# ICSSM0_COMMON_0_IEP0 register map
Vendor: Texas Instruments
Peripheral module from a debugger description file (folder am62x).
Registers are 32-bit, read-write, reset 0x0 unless marked. A register's access mark holds for its fields unless they carry their own. Offsets are as the file gives them; lines under a group give offsets from that group; [hi:lo] are bit positions; {n}, {i} and the like mark numbered series; 'fields as' and 'values as' point back to an identical list; <NAME> marks a mode.

## ICSSM0_COMMON_0_IEP0
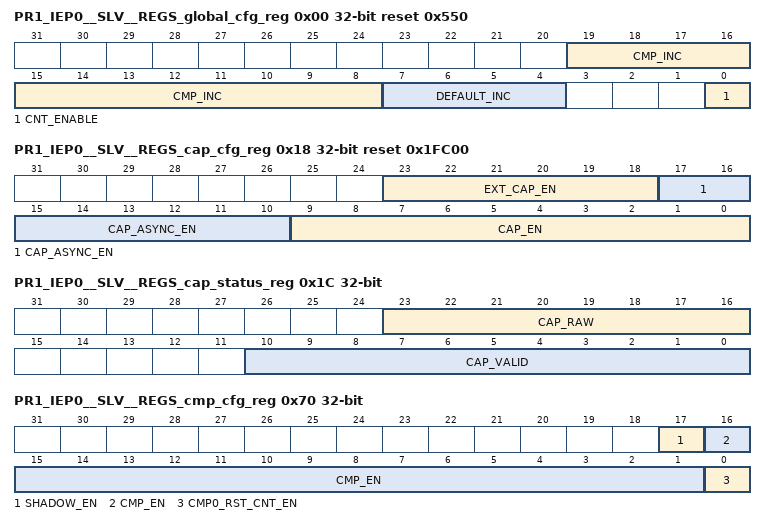
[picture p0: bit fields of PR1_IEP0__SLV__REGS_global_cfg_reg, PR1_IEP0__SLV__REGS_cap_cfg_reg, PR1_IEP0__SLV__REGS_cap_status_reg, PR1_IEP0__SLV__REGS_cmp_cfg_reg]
0x00 PR1_IEP0__SLV__REGS_global_cfg_reg reset 0x550
  [19:8] CMP_INC, [7:4] DEFAULT_INC, [0] CNT_ENABLE
0x04 PR1_IEP0__SLV__REGS_global_status_reg access not given
  [0] CNT_OVF — (access R/W1TC)
0x08 PR1_IEP0__SLV__REGS_compen_reg
  [22:0] COMPEN_CNT
0x0C PR1_IEP0__SLV__REGS_slow_compen_reg
  [31:0] SLOW_COMPEN_CNT
0x10 PR1_IEP0__SLV__REGS_count_reg0
  [31:0] COUNT_LO
0x14 PR1_IEP0__SLV__REGS_count_reg1
  [31:0] COUNT_HI
0x18 PR1_IEP0__SLV__REGS_cap_cfg_reg reset 0x1FC00
  [23:18] EXT_CAP_EN, [17:10] CAP_ASYNC_EN, [9:0] CAP_EN
0x1C PR1_IEP0__SLV__REGS_cap_status_reg ro
  [23:16] CAP_RAW, [10:0] CAP_VALID
{0x20+8i} PR1_IEP0__SLV__REGS_capr{i}_reg0 ro (i=0..6)
  [31:0] CAPR{i}_0
{0x24+8i} PR1_IEP0__SLV__REGS_capr{i}_reg1 ro (i=0..6)
  [31:0] CAPR{i}_1
0x58 PR1_IEP0__SLV__REGS_capf6_reg0 ro
  [31:0] CAPF6_0
0x5C PR1_IEP0__SLV__REGS_capf6_reg1 ro
  [31:0] CAPF6_1
0x60 PR1_IEP0__SLV__REGS_capr7_reg0 ro
  [31:0] CAPR7_0
0x64 PR1_IEP0__SLV__REGS_capr7_reg1 ro
  [31:0] CAPR7_1
0x68 PR1_IEP0__SLV__REGS_capf7_reg0 ro
  [31:0] CAPF7_0
0x6C PR1_IEP0__SLV__REGS_capf7_reg1 ro
  [31:0] CAPF7_1
0x70 PR1_IEP0__SLV__REGS_cmp_cfg_reg
  [17] SHADOW_EN, [16:1] CMP_EN, [0] CMP0_RST_CNT_EN
0x74 PR1_IEP0__SLV__REGS_cmp_status_reg access not given
  [15:0] CMP_STATUS — (access R/W1TC)
{0x78+8i} PR1_IEP0__SLV__REGS_cmp{i}_reg0 (i=0..7)
  [31:0] CMP{i}_0
{0x7C+8i} PR1_IEP0__SLV__REGS_cmp{i}_reg1 (i=0..7)
  [31:0] CMP{i}_1
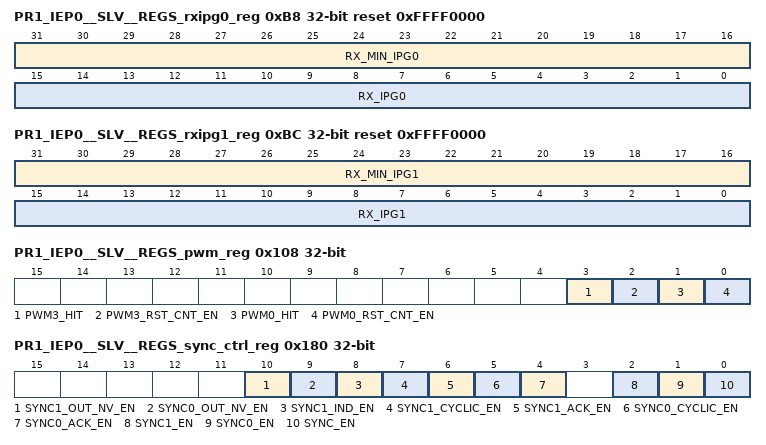
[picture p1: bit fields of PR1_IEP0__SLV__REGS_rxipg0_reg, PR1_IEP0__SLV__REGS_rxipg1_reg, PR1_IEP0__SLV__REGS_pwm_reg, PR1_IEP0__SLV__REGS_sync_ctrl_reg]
0xB8 PR1_IEP0__SLV__REGS_rxipg0_reg access per field reset 0xFFFF0000
  [31:16] RX_MIN_IPG0 rw, [15:0] RX_IPG0 ro
0xBC PR1_IEP0__SLV__REGS_rxipg1_reg access per field reset 0xFFFF0000
  [31:16] RX_MIN_IPG1 rw, [15:0] RX_IPG1 ro
{0x80+8i} PR1_IEP0__SLV__REGS_cmp{i}_reg0 (i=8..15)
  [31:0] CMP{i}_0
{0x84+8i} PR1_IEP0__SLV__REGS_cmp{i}_reg1 (i=8..15)
  [31:0] CMP{i}_1
0x100 PR1_IEP0__SLV__REGS_count_reset_val_reg0
  [31:0] RESET_VAL_0
0x104 PR1_IEP0__SLV__REGS_count_reset_val_reg1
  [31:0] RESET_VAL_1
0x108 PR1_IEP0__SLV__REGS_pwm_reg access not given
  [3] PWM3_HIT — (access R/W1TC)
  [2] PWM3_RST_CNT_EN rw
  [1] PWM0_HIT — (access R/W1TC)
  [0] PWM0_RST_CNT_EN rw
{0x10C+8i} PR1_IEP0__SLV__REGS_capr{i}_bi_reg0 ro (i=0..6)
  [31:0] CAPR{i}_0
{0x110+8i} PR1_IEP0__SLV__REGS_capr{i}_bi_reg1 ro (i=0..6)
  [31:0] CAPR{i}_1
0x144 PR1_IEP0__SLV__REGS_capf6_bi_reg0 ro
  [31:0] CAPF6_0
0x148 PR1_IEP0__SLV__REGS_capf6_bi_reg1 ro
  [31:0] CAPF6_1
0x14C PR1_IEP0__SLV__REGS_capr7_bi_reg0 ro
  [31:0] CAPR7_0
0x150 PR1_IEP0__SLV__REGS_capr7_bi_reg1 ro
  [31:0] CAPR7_1
0x154 PR1_IEP0__SLV__REGS_capf7_bi_reg0 ro
  [31:0] CAPF7_0
0x158 PR1_IEP0__SLV__REGS_capf7_bi_reg1 ro
  [31:0] CAPF7_1
0x180 PR1_IEP0__SLV__REGS_sync_ctrl_reg
  [10] SYNC1_OUT_NV_EN, [9] SYNC0_OUT_NV_EN, [8] SYNC1_IND_EN, [7] SYNC1_CYCLIC_EN, [6] SYNC1_ACK_EN, [5] SYNC0_CYCLIC_EN, [4] SYNC0_ACK_EN, [2] SYNC1_EN, [1] SYNC0_EN, [0] SYNC_EN
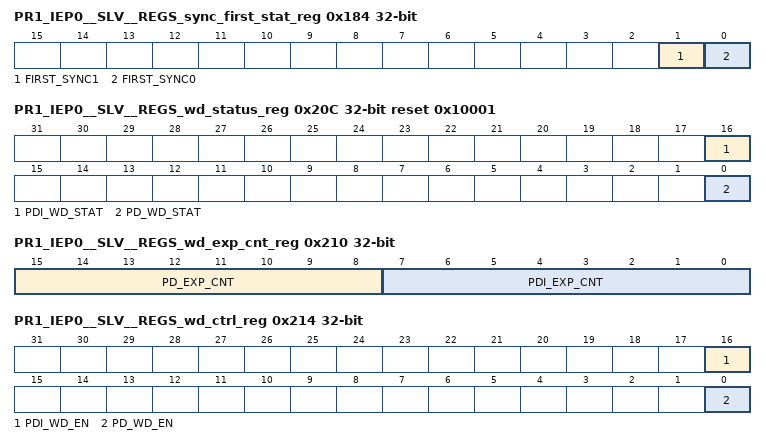
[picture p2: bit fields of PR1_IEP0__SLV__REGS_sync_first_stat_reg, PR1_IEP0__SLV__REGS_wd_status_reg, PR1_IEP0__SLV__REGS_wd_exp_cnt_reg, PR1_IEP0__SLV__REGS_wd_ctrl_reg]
0x184 PR1_IEP0__SLV__REGS_sync_first_stat_reg ro
  [1] FIRST_SYNC1, [0] FIRST_SYNC0
0x188 PR1_IEP0__SLV__REGS_sync0_stat_reg ro
  [0] SYNC0_PEND
0x18C PR1_IEP0__SLV__REGS_sync1_stat_reg ro
  [0] SYNC1_PEND
0x190 PR1_IEP0__SLV__REGS_sync_pwidth_reg
  [31:0] SYNC_HPW
0x194 PR1_IEP0__SLV__REGS_sync0_period_reg reset 0x1
  [31:0] SYNC0_PERIOD
0x198 PR1_IEP0__SLV__REGS_sync1_delay_reg
  [31:0] SYNC1_DELAY
0x19C PR1_IEP0__SLV__REGS_sync_start_reg
  [31:0] SYNC_START
0x200 PR1_IEP0__SLV__REGS_wd_prediv_reg reset 0x4E20
  [15:0] PRE_DIV
0x204 PR1_IEP0__SLV__REGS_pdi_wd_tim_reg reset 0x3E8
  [15:0] PDI_WD_TIME
0x208 PR1_IEP0__SLV__REGS_pd_wd_tim_reg reset 0x3E8
  [15:0] PD_WD_TIME
0x20C PR1_IEP0__SLV__REGS_wd_status_reg ro reset 0x10001
  [16] PDI_WD_STAT, [0] PD_WD_STAT
0x210 PR1_IEP0__SLV__REGS_wd_exp_cnt_reg
  [15:8] PD_EXP_CNT, [7:0] PDI_EXP_CNT
0x214 PR1_IEP0__SLV__REGS_wd_ctrl_reg
  [16] PDI_WD_EN, [0] PD_WD_EN
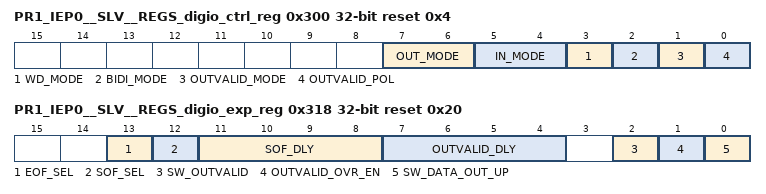
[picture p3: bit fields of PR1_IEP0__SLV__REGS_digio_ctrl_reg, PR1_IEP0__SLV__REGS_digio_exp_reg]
0x300 PR1_IEP0__SLV__REGS_digio_ctrl_reg access per field reset 0x4
  [7:6] OUT_MODE rw, [5:4] IN_MODE rw, [3] WD_MODE rw, [2] BIDI_MODE ro, [1] OUTVALID_MODE rw, [0] OUTVALID_POL ro
0x304 PR1_IEP0__SLV__REGS_digio_status_reg ro
  [31:0] DIGIO_STAT
0x308 PR1_IEP0__SLV__REGS_digio_data_in_reg ro
  [31:0] DATA_IN
0x30C PR1_IEP0__SLV__REGS_digio_data_in_raw_reg ro
  [31:0] DATA_IN_RAW
0x310 PR1_IEP0__SLV__REGS_digio_data_out_reg
  [31:0] DATA_OUT
0x314 PR1_IEP0__SLV__REGS_digio_data_out_en_reg
  [31:0] DATA_OUT_EN
0x318 PR1_IEP0__SLV__REGS_digio_exp_reg reset 0x20
  [13] EOF_SEL, [12] SOF_SEL, [11:8] SOF_DLY, [7:4] OUTVALID_DLY, [2] SW_OUTVALID, [1] OUTVALID_OVR_EN, [0] SW_DATA_OUT_UP
